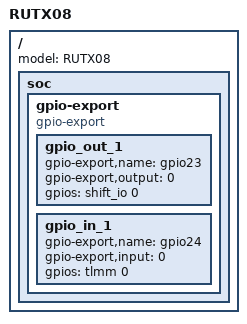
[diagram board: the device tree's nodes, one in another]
#include "qcom-ipq4018-rutx-shiftreg.dtsi"

/ {
	model = "RUTX08";

	soc {
		gpio-export {
			compatible = "gpio-export";
			#size-cells = <0>;

			gpio_out_1 {
				gpio-export,name = "gpio23";
				gpio-export,output = <0>;
				gpios = <&shift_io 0 GPIO_ACTIVE_HIGH>;
			};

			gpio_in_1 {
				gpio-export,name = "gpio24";
				gpio-export,input = <0>;
				gpios = <&tlmm 0 GPIO_ACTIVE_HIGH>;
			};
		};
	};
};
